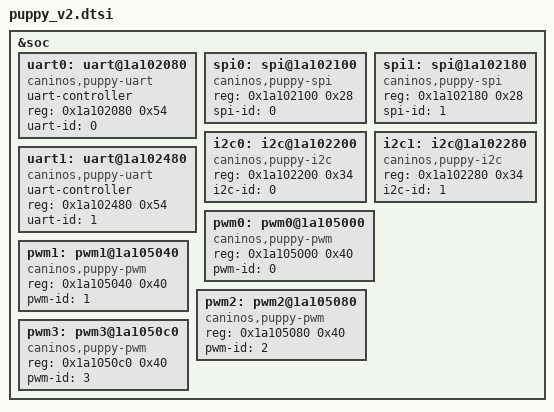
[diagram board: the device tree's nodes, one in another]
#include "puppy.dtsi"

&soc {
	uart0: uart@1a102080 {
		compatible = "caninos,puppy-uart";
		uart-controller;
		reg = <0x1a102080 0x54>;
		uart-id = <0>;
	};

	spi0: spi@1a102100 {
		compatible = "caninos,puppy-spi";
		#address-cells = <1>;
		#size-cells = <0>;
		reg = <0x1a102100 0x28>;
		spi-id = <0>;
	};

	spi1: spi@1a102180 {
		compatible = "caninos,puppy-spi";
		#address-cells = <1>;
		#size-cells = <0>;
		reg = <0x1a102180 0x28>;
		spi-id = <1>;
	};

	i2c0: i2c@1a102200 {
		compatible = "caninos,puppy-i2c";
		#address-cells = <1>;
		#size-cells = <0>;
		reg = <0x1a102200 0x34>;
		i2c-id = <0>;
	};

	i2c1: i2c@1a102280 {
		compatible = "caninos,puppy-i2c";
		#address-cells = <1>;
		#size-cells = <0>;
		reg = <0x1a102280 0x34>;
		i2c-id = <1>;
	};

	uart1: uart@1a102480 {
		compatible = "caninos,puppy-uart";
		uart-controller;
		reg = <0x1a102480 0x54>;
		uart-id = <1>;
	};

	pwm0: pwm0@1a105000 {
		compatible = "caninos,puppy-pwm";
		reg = <0x1a105000 0x40>;
		pwm-id = <0>;
		#pwm-cells = <3>;
	};

	pwm1: pwm1@1a105040 {
		compatible = "caninos,puppy-pwm";
		reg = <0x1a105040 0x40>;
		pwm-id = <1>;
		#pwm-cells = <3>;
	};

	pwm2: pwm2@1a105080 {
		compatible = "caninos,puppy-pwm";
		reg = <0x1a105080 0x40>;
		pwm-id = <2>;
		#pwm-cells = <3>;
	};

	pwm3: pwm3@1a1050c0 {
		compatible = "caninos,puppy-pwm";
		reg = <0x1a1050c0 0x40>;
		pwm-id = <3>;
		#pwm-cells = <3>;
	};
};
